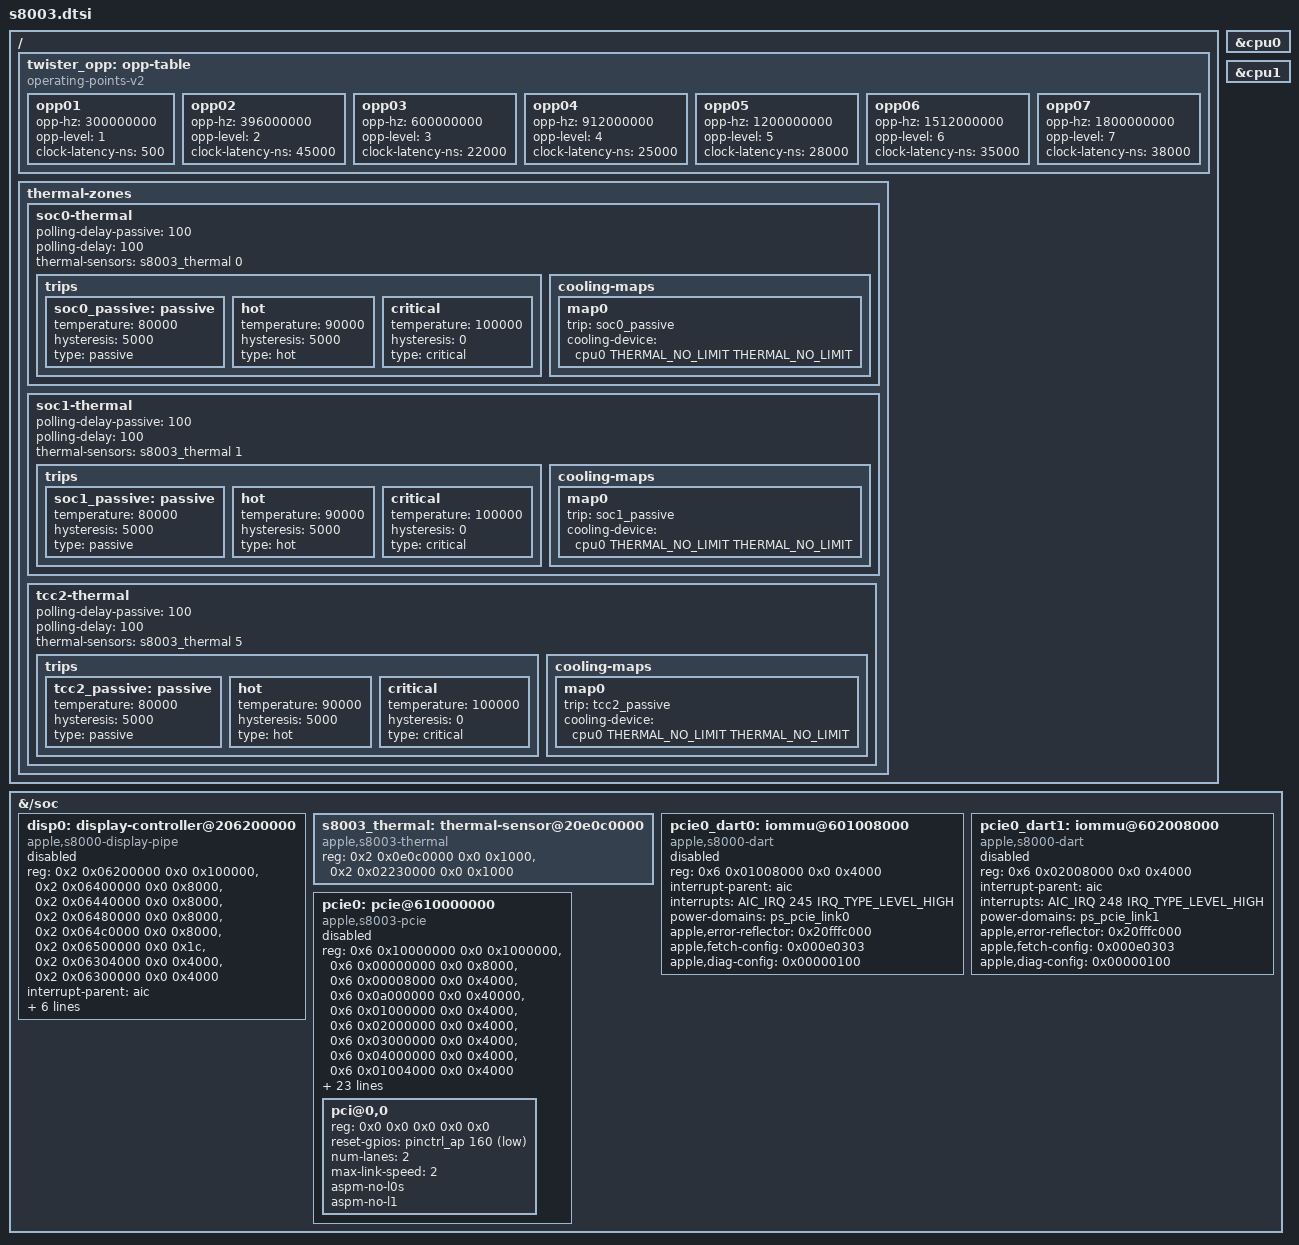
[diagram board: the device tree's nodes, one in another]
// SPDX-License-Identifier: GPL-2.0+ OR MIT
/*
 * Apple S8003 "A9" (TSMC) SoC
 *
 * Other names: H8P, "Malta"
 *
 * Copyright (c) 2024, Nick Chan <towinchenmi@gmail.com>
 */

#include "s800-0-3.dtsi"
#include <dt-bindings/thermal/thermal.h>

/ {
	twister_opp: opp-table {
		compatible = "operating-points-v2";

		opp01 {
			opp-hz = /bits/ 64 <300000000>;
			opp-level = <1>;
			clock-latency-ns = <500>;
		};
		opp02 {
			opp-hz = /bits/ 64 <396000000>;
			opp-level = <2>;
			clock-latency-ns = <45000>;
		};
		opp03 {
			opp-hz = /bits/ 64 <600000000>;
			opp-level = <3>;
			clock-latency-ns = <22000>;
		};
		opp04 {
			opp-hz = /bits/ 64 <912000000>;
			opp-level = <4>;
			clock-latency-ns = <25000>;
		};
		opp05 {
			opp-hz = /bits/ 64 <1200000000>;
			opp-level = <5>;
			clock-latency-ns = <28000>;
		};
		opp06 {
			opp-hz = /bits/ 64 <1512000000>;
			opp-level = <6>;
			clock-latency-ns = <35000>;
		};
		opp07 {
			opp-hz = /bits/ 64 <1800000000>;
			opp-level = <7>;
			clock-latency-ns = <38000>;
		};
#if 0
		/* Not available until CPU deep sleep is implemented */
		opp08 {
			opp-hz = /bits/ 64 <1844000000>;
			opp-level = <8>;
			clock-latency-ns = <38000>;
			turbo-mode;
		};
#endif
	};
};

&cpu0 {
	#cooling-cells = <2>;
};

&cpu1 {
	#cooling-cells = <2>;
};

&{/soc} {
	/*
	 * ADT disp0 ("adbe0,s8000"). The pipe reads through dart-disp0,
	 * which iBoot leaves in bypass and which stays undescribed.
	 */
	disp0: display-controller@206200000 {
		compatible = "apple,s8000-display-pipe";
		reg = <0x2 0x06200000 0x0 0x100000>,
		      <0x2 0x06400000 0x0 0x8000>,
		      <0x2 0x06440000 0x0 0x8000>,
		      <0x2 0x06480000 0x0 0x8000>,
		      <0x2 0x064c0000 0x0 0x8000>,
		      <0x2 0x06500000 0x0 0x1c>,
		      <0x2 0x06304000 0x0 0x4000>,
		      <0x2 0x06300000 0x0 0x4000>;
		reg-names = "adp", "disp-a", "disp-b", "disp-c", "disp-d",
			    "side", "dart0", "dart1";
		interrupt-parent = <&aic>;
		interrupts = <AIC_IRQ 140 IRQ_TYPE_LEVEL_HIGH>,
			     <AIC_IRQ 143 IRQ_TYPE_LEVEL_HIGH>,
			     <AIC_IRQ 144 IRQ_TYPE_LEVEL_HIGH>,
			     <AIC_IRQ 145 IRQ_TYPE_LEVEL_HIGH>,
			     <AIC_IRQ 146 IRQ_TYPE_LEVEL_HIGH>;
		power-domains = <&ps_disp0>, <&ps_dp>;
		status = "disabled";
	};

	/* ADT tempsensor,s8000 (AppleT700XTempSensor): SOC and TCC blocks */
	s8003_thermal: thermal-sensor@20e0c0000 {
		compatible = "apple,s8003-thermal";
		reg = <0x2 0x0e0c0000 0x0 0x1000>,
		      <0x2 0x02230000 0x0 0x1000>;
		reg-names = "soc", "tcc";
		#thermal-sensor-cells = <1>;
	};

	/*
	 * error-reflector, fetch-config and diag-config are the ADT
	 * dart-apcie0/1 values, which iOS programs at every DART init.
	 */
	pcie0_dart0: iommu@601008000 {
		compatible = "apple,s8000-dart", "apple,s5l8960x-dart";
		reg = <0x6 0x01008000 0x0 0x4000>;
		#iommu-cells = <5>;
		interrupt-parent = <&aic>;
		interrupts = <AIC_IRQ 245 IRQ_TYPE_LEVEL_HIGH>;
		power-domains = <&ps_pcie_link0>;
		apple,error-reflector = /bits/ 64 <0x20fffc000>;
		apple,fetch-config = <0x000e0303>;
		apple,diag-config = <0x00000100>;
		status = "disabled";
	};

	pcie0_dart1: iommu@602008000 {
		compatible = "apple,s8000-dart", "apple,s5l8960x-dart";
		reg = <0x6 0x02008000 0x0 0x4000>;
		#iommu-cells = <5>;
		interrupt-parent = <&aic>;
		interrupts = <AIC_IRQ 248 IRQ_TYPE_LEVEL_HIGH>;
		power-domains = <&ps_pcie_link1>;
		apple,error-reflector = /bits/ 64 <0x20fffc000>;
		apple,fetch-config = <0x000e0303>;
		apple,diag-config = <0x00000100>;
		status = "disabled";
	};

	/*
	 * The TSMC part has the same PCIe PHY ("phy-ip" block) as T8010.
	 * The S8000's root complex has no phy-ip region and isn't described.
	 */
	pcie0: pcie@610000000 {
		compatible = "apple,s8003-pcie";
		device_type = "pci";

		reg = <0x6 0x10000000 0x0 0x1000000>,
		      <0x6 0x00000000 0x0 0x8000>,
		      <0x6 0x00008000 0x0 0x4000>,
		      <0x6 0x0a000000 0x0 0x40000>,
		      <0x6 0x01000000 0x0 0x4000>,
		      <0x6 0x02000000 0x0 0x4000>,
		      <0x6 0x03000000 0x0 0x4000>,
		      <0x6 0x04000000 0x0 0x4000>,
		      <0x6 0x01004000 0x0 0x4000>;
		reg-names = "config", "rc", "phy", "phy-ip",
			    "port0", "port1", "port2", "port3",
			    "nvmmu";

		interrupt-parent = <&aic>;
		interrupts = <AIC_IRQ 244 IRQ_TYPE_LEVEL_HIGH>,
			     <AIC_IRQ 247 IRQ_TYPE_LEVEL_HIGH>,
			     <AIC_IRQ 250 IRQ_TYPE_LEVEL_HIGH>,
			     <AIC_IRQ 253 IRQ_TYPE_LEVEL_HIGH>,
			     <AIC_IRQ 246 IRQ_TYPE_EDGE_RISING>;
		interrupt-names = "port0", "port1", "port2", "port3",
				  "nvmmu";

		msi-controller;
		msi-parent = <&pcie0>;
		msi-ranges = <&aic AIC_IRQ 256 IRQ_TYPE_EDGE_RISING 32>;
		apple,msi-doorbell = <0xbffff000>;
		apple,nvmmu-iova = <0xbc000000>;
		apple,nvme-hmb = <&nvme_hmb>;

		/*
		 * DART windows from the ADT dart-apcie0/1 vm-offset and
		 * vm-size. The root complex decodes 0x40000000 (NVMMU
		 * FlatDMA), 0x80000000 (DART), 0xbc000000 (NVMMU SART) and
		 * 0xbffff000 (MSI) inbound; no dma-ranges, as one ending below
		 * RAM would empty ZONE_DMA/DMA32.
		 */
		iommu-map = <0x100 &pcie0_dart0 0 0x0 0x80000000 0x0 0x3c000000 1>,
			    <0x200 &pcie0_dart1 0 0x0 0x80000000 0x0 0x3ffff000 1>;
		iommu-map-mask = <0xff00>;

		#address-cells = <3>;
		#size-cells = <2>;
		#interrupt-cells = <1>;
		interrupt-controller;
		bus-range = <0x00 0x0f>;
		ranges = <0x03000000 0x0 0xc0000000
			  0x7 0xc0000000 0x0 0x40000000>;

		/* ADT apcie clock-gates: pcie, pcie_aux, pcie_ref, pcie_link0..3 */
		power-domains = <&ps_pcie>, <&ps_pcie_aux>, <&ps_pcie_ref>,
				<&ps_pcie_link0>, <&ps_pcie_link1>,
				<&ps_pcie_link2>, <&ps_pcie_link3>;
		power-domain-names = "core", "aux", "ref", "link0", "link1",
				     "link2", "link3";
		status = "disabled";

		/*
		 * Storage. PERST# from the ADT pci-bridge0 function-perst;
		 * CLKREQ# stays in its peripheral function.
		 */
		pci@0,0 {
			device_type = "pci";
			reg = <0x0 0x0 0x0 0x0 0x0>;
			reset-gpios = <&pinctrl_ap 160 GPIO_ACTIVE_LOW>;
			num-lanes = <2>;
			max-link-speed = <2>;
			/*
			 * iOS pairs ASPM L1 with an L1SS, LTR and CLKREQ#
			 * setup that isn't done here.
			 */
			aspm-no-l0s;
			aspm-no-l1;

			#address-cells = <3>;
			#size-cells = <2>;
			ranges;
		};
	};
};

/ {
	/*
	 * Trips are margins below the 100 C alarm iBoot programs, not iOS's
	 * skin temperature policy.
	 */
	thermal-zones {
		soc0-thermal {
			polling-delay-passive = <100>;
			polling-delay = <100>;
			thermal-sensors = <&s8003_thermal 0>;

			trips {
				soc0_passive: passive {
					temperature = <80000>;
					hysteresis = <5000>;
					type = "passive";
				};

				hot {
					temperature = <90000>;
					hysteresis = <5000>;
					type = "hot";
				};

				critical {
					temperature = <100000>;
					hysteresis = <0>;
					type = "critical";
				};
			};

			cooling-maps {
				map0 {
					trip = <&soc0_passive>;
					cooling-device = <&cpu0 THERMAL_NO_LIMIT THERMAL_NO_LIMIT>;
				};
			};
		};

		soc1-thermal {
			polling-delay-passive = <100>;
			polling-delay = <100>;
			thermal-sensors = <&s8003_thermal 1>;

			trips {
				soc1_passive: passive {
					temperature = <80000>;
					hysteresis = <5000>;
					type = "passive";
				};

				hot {
					temperature = <90000>;
					hysteresis = <5000>;
					type = "hot";
				};

				critical {
					temperature = <100000>;
					hysteresis = <0>;
					type = "critical";
				};
			};

			cooling-maps {
				map0 {
					trip = <&soc1_passive>;
					cooling-device = <&cpu0 THERMAL_NO_LIMIT THERMAL_NO_LIMIT>;
				};
			};
		};

		tcc2-thermal {
			polling-delay-passive = <100>;
			polling-delay = <100>;
			thermal-sensors = <&s8003_thermal 5>;

			trips {
				tcc2_passive: passive {
					temperature = <80000>;
					hysteresis = <5000>;
					type = "passive";
				};

				hot {
					temperature = <90000>;
					hysteresis = <5000>;
					type = "hot";
				};

				critical {
					temperature = <100000>;
					hysteresis = <0>;
					type = "critical";
				};
			};

			cooling-maps {
				map0 {
					trip = <&tcc2_passive>;
					cooling-device = <&cpu0 THERMAL_NO_LIMIT THERMAL_NO_LIMIT>;
				};
			};
		};
	};
};

/*
 * The A9 was made by two separate fabs on two different process
 * nodes: Samsung made the S8000 (APL0898) on 14nm and TSMC made
 * the S8003 (APL1022) on 16nm. There are some minor differences
 * such as timing in cpufreq state transistions.
 */
